# AT32F402xx_v2 register map
Vendor: Keil; Series: AT32F402; File version: 1.0
CPU: CM4 r0p1, little endian, no MPU, FPU, 4 interrupt priority bits
Registers are 32-bit, read-write, reset 0x0 unless marked. A register's access mark holds for its fields unless they carry their own. Offsets are from the block's base; [hi:lo] are bit positions.

## USART1 — Universal synchronous asynchronous receiver transmitter
Base 0x40011000
Same registers: USART2 0x40004400, USART3 0x40004800, USART4 0x40004C00, USART5 0x40005000, UART7 0x40007800, UART8 0x40007C00, USART6 0x40011400
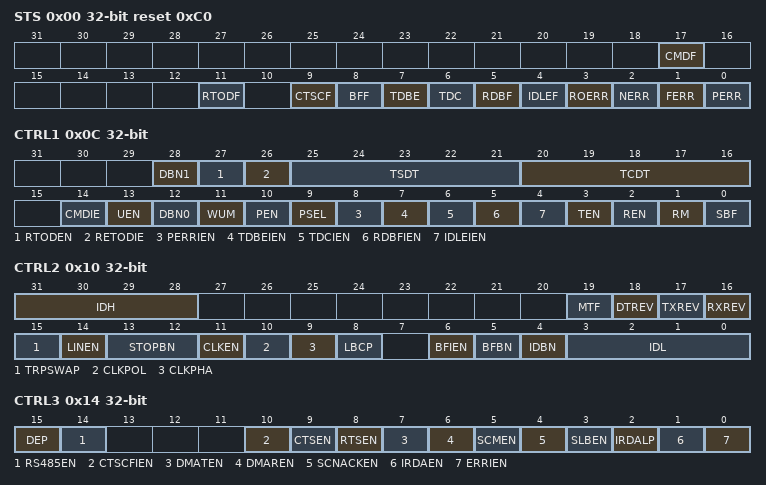
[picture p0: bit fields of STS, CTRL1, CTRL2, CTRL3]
0x00 STS reset 0xC0 — Status register
  [17] CMDF — Character match detection flag
  [11] RTODF — Reiceiver time out detection flag
  [9] CTSCF — CTS change flag
  [8] BFF — Break frame flag
  [7] TDBE ro — Transmit data buffer empty
  [6] TDC — Transmit data complete
  [5] RDBF — Receive data buffer full
  [4] IDLEF ro — IDLE flag
  [3] ROERR ro — Receiver overflow error
  [2] NERR ro — Noise error
  [1] FERR ro — Framing error
  [0] PERR ro — Parity error
0x04 DT — Data register
  [8:0] DT — Data value
0x08 BAUDR — Baud rate register
  [15:0] DIV — Division
0x0C CTRL1 — Control register 1
  [28] DBN1 — high bit for Data bit num
  [27] RTODEN — Receiver time out detection enable
  [26] RETODIE — Receiver time out detection interrupt enable
  [25:21] TSDT — transmit start delay time
  [20:16] TCDT — transmit complete delay time
  [14] CMDIE — Character match detection interrupt enable
  [13] UEN — USART enable
  [12] DBN0 — low bit for Data bit num
  [11] WUM — Wake up mode
  [10] PEN — Parity enable
  [9] PSEL — Parity selection
  [8] PERRIEN — PERR interrupt enable
  [7] TDBEIEN — TDBE interrupt enable
  [6] TDCIEN — TDC interrupt enable
  [5] RDBFIEN — RDBF interrupt enable
  [4] IDLEIEN — IDLE interrupt enable
  [3] TEN — Transmitter enable
  [2] REN — Receiver enable
  [1] RM — Receiver mute
  [0] SBF — Send break frame
0x10 CTRL2 — Control register 2
  [31:28] IDH — bit 7-4 for usart identification
  [19] MTF — MSB transmit first
  [18] DTREV — DT register polarity reverse
  [17] TXREV — TX polarity reverse
  [16] RXREV — RX polarity reverse
  [15] TRPSWAP — Transmit receive pin swap
  [14] LINEN — LIN mode enable
  [13:12] STOPBN — STOP bit num
  [11] CLKEN — Clock enable
  [10] CLKPOL — Clock polarity
  [9] CLKPHA — Clock phase
  [8] LBCP — Last bit clock pulse
  [6] BFIEN — Break frame interrupt enable
  [5] BFBN — Break frame bit num
  [4] IDBN — Identification bit num
  [3:0] IDL — bit 3-0 for usart identification
0x14 CTRL3 — Control register 3
  [15] DEP — DE polarity selection
  [14] RS485EN — RS485 enable
  [10] CTSCFIEN — CTSCF interrupt enable
  [9] CTSEN — CTS enable
  [8] RTSEN — RTS enable
  [7] DMATEN — DMA transmitter enable
  [6] DMAREN — DMA receiver enable
  [5] SCMEN — Smartcard mode enable
  [4] SCNACKEN — Smartcard NACK enable
  [3] SLBEN — Single line bidirectional half-duplex enable
  [2] IRDALP — IrDA low-power mode
  [1] IRDAEN — IrDA enable
  [0] ERRIEN — Error interrupt enable
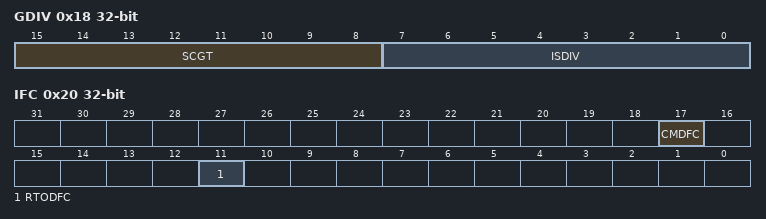
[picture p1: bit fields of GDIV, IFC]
0x18 GDIV — Guard time and division register
  [15:8] SCGT — Smart card guard time value
  [7:0] ISDIV — IrDA/smartcard division value
0x1C RTOV — Receiver time out value register
  [23:0] RTOV — Receiver time out value
0x20 IFC — Interruption flag clear register
  [17] CMDFC — Character match detection flag clear
  [11] RTODFC — Receiver time out detection flag clear

## ADCCOM — ADC common area
Base 0x40012300
0x04 CCTRL — Common control register
  [19:16] ADCDIV — ADC division

## DEBUG — Debug support
Base 0xE0042000
0x00 IDCODE ro — DEBUG IDCODE
  [31:0] PID — Product ID
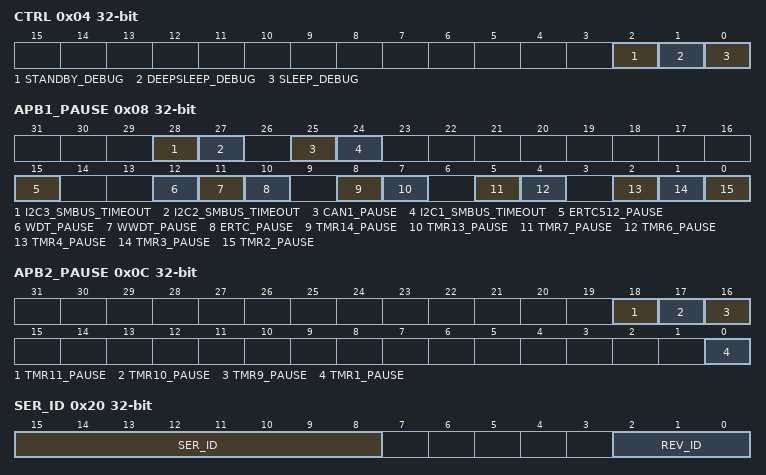
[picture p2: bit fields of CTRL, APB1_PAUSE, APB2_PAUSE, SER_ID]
0x04 CTRL — DEBUG CTRL
  [2] STANDBY_DEBUG, [1] DEEPSLEEP_DEBUG, [0] SLEEP_DEBUG
0x08 APB1_PAUSE — DEBUG APB1 PAUSE
  [28] I2C3_SMBUS_TIMEOUT, [27] I2C2_SMBUS_TIMEOUT, [25] CAN1_PAUSE, [24] I2C1_SMBUS_TIMEOUT, [15] ERTC512_PAUSE, [12] WDT_PAUSE, [11] WWDT_PAUSE, [10] ERTC_PAUSE, [8] TMR14_PAUSE, [7] TMR13_PAUSE, [5] TMR7_PAUSE, [4] TMR6_PAUSE, [2] TMR4_PAUSE, [1] TMR3_PAUSE, [0] TMR2_PAUSE
0x0C APB2_PAUSE — DEBUG APB2 PAUSE
  [18] TMR11_PAUSE, [17] TMR10_PAUSE, [16] TMR9_PAUSE, [0] TMR1_PAUSE
0x20 SER_ID ro — SERIES ID
  [15:8] SER_ID — series ID
  [2:0] REV_ID — version ID
